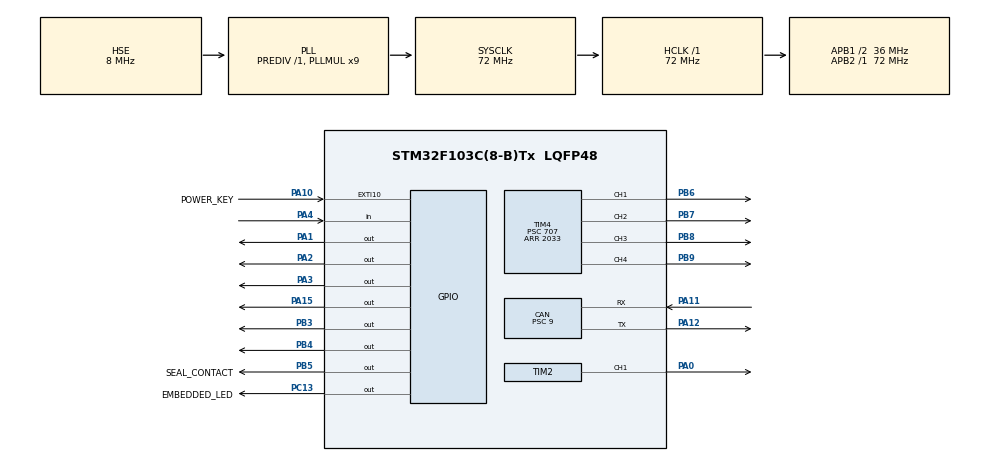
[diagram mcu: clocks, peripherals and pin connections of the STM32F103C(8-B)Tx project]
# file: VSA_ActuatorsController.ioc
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CAN.BS1=CAN_BS1_13TQ
CAN.BS2=CAN_BS2_2TQ
CAN.CalculateBaudRate=250000
CAN.CalculateTimeBit=4000
CAN.CalculateTimeQuantum=250.0
CAN.Prescaler=9
Mcu.Family=STM32F1
Mcu.Name=STM32F103C(8-B)Tx
Mcu.Package=LQFP48
NVIC.EXTI15_10_IRQn=true\:0\:0\:false\:false\:true\:true\:true\:true
NVIC.PriorityGroup=NVIC_PRIORITYGROUP_4
NVIC.USB_LP_CAN1_RX0_IRQn=true\:0\:0\:false\:false\:true\:true\:true\:true
PA0-WKUP.Signal=S_TIM2_CH1_ETR
PA1.Signal=GPIO_Output
PA10.GPIO_Label=POWER_KEY
PA10.GPIO_ModeDefaultEXTI=GPIO_MODE_IT_RISING_FALLING
PA10.GPIO_PuPd=GPIO_PULLUP
PA10.Signal=GPXTI10
PA11.Mode=CAN_Activate
PA11.Signal=CAN_RX
PA12.Mode=CAN_Activate
PA12.Signal=CAN_TX
PA14.Signal=SYS_JTCK-SWCLK
PA15.Signal=GPIO_Output
PA2.Signal=GPIO_Output
PA3.Signal=GPIO_Output
PA4.Signal=GPIO_Input
PB3.Signal=GPIO_Output
PB4.Signal=GPIO_Output
PB5.GPIO_Label=SEAL_CONTACT
PB5.Signal=GPIO_Output
PB6.Signal=S_TIM4_CH1
PB7.Signal=S_TIM4_CH2
PB8.Signal=S_TIM4_CH3
PB9.Signal=S_TIM4_CH4
PC13-TAMPER-RTC.GPIO_Label=EMBEDDED_LED
PC13-TAMPER-RTC.Signal=GPIO_Output
PD0-OSC_IN.Mode=HSE-External-Oscillator
PD0-OSC_IN.Signal=RCC_OSC_IN
PD1-OSC_OUT.Mode=HSE-External-Oscillator
PD1-OSC_OUT.Signal=RCC_OSC_OUT
ProjectManager.HeapSize=0x200
ProjectManager.StackSize=0x400
ProjectManager.TargetToolchain=STM32CubeIDE
RCC.AHBFreq_Value=72000000
RCC.APB1CLKDivider=RCC_HCLK_DIV2
RCC.APB1Freq_Value=36000000
RCC.APB1TimFreq_Value=72000000
RCC.APB2Freq_Value=72000000
RCC.APB2TimFreq_Value=72000000
RCC.HCLKFreq_Value=72000000
RCC.PLLMUL=RCC_PLL_MUL9
RCC.PLLSourceVirtual=RCC_PLLSOURCE_HSE
RCC.SYSCLKFreq_VALUE=72000000
RCC.SYSCLKSource=RCC_SYSCLKSOURCE_PLLCLK
RCC.USBFreq_Value=72000000
SH.S_TIM2_CH1_ETR.0=TIM2_CH1,PWM Generation1 CH1
SH.S_TIM4_CH1.0=TIM4_CH1,PWM Generation1 CH1
SH.S_TIM4_CH2.0=TIM4_CH2,PWM Generation2 CH2
SH.S_TIM4_CH3.0=TIM4_CH3,PWM Generation3 CH3
SH.S_TIM4_CH4.0=TIM4_CH4,PWM Generation4 CH4
TIM2.Channel-PWM\ Generation1\ CH1=TIM_CHANNEL_1
TIM2.Period=255
TIM2.Prescaler=250
TIM4.Channel-PWM\ Generation1\ CH1=TIM_CHANNEL_1
TIM4.Channel-PWM\ Generation2\ CH2=TIM_CHANNEL_2
TIM4.Channel-PWM\ Generation3\ CH3=TIM_CHANNEL_3
TIM4.Channel-PWM\ Generation4\ CH4=TIM_CHANNEL_4
TIM4.Period=2033
TIM4.Prescaler=707
VP_SYS_VS_ND.Mode=No_Debug
board=custom

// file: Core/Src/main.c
/* USER CODE BEGIN Header */
/**
  ******************************************************************************
  * @file           : main.c
  * @brief          : Main program body
  ******************************************************************************
  * @attention
  *
  * Copyright (c) 2026 STMicroelectronics.
  * All rights reserved.
  *
  * This software is licensed under terms that can be found in the LICENSE file
  * in the root directory of this software component.
  * If no LICENSE file comes with this software, it is provided AS-IS.
  *
  ******************************************************************************
  */
/* USER CODE END Header */
#include "main.h"
#include "vsa_actuators_controller.h"

void SystemClock_Config(void);

int main(void)
{
  HAL_Init();

  /* Configure the system clock */
  SystemClock_Config();

  /* Initialize all configured peripherals */
  MX_GPIO_Init();
  MX_CAN_Init();
  MX_TIM2_Init();
  MX_TIM4_Init();

  // Initialize Timers
  HAL_TIM_Base_Start(&htim2);
  HAL_TIM_Base_Start(&htim4);

  // Initialize PWM Pins
  HAL_TIM_PWM_Start(&htim2, TIM_CHANNEL_1); // Thruster Controller
  HAL_TIM_PWM_Start(&htim4, TIM_CHANNEL_1); // Servo 1
  HAL_TIM_PWM_Start(&htim4, TIM_CHANNEL_2); // Servo 2
  HAL_TIM_PWM_Start(&htim4, TIM_CHANNEL_3); // Servo 2
  HAL_TIM_PWM_Start(&htim4, TIM_CHANNEL_4); // Servo 3

  while (1)
  {
	  run();
  }
}

void SystemClock_Config(void)
{
  RCC_OscInitTypeDef RCC_OscInitStruct = {0};
  RCC_ClkInitTypeDef RCC_ClkInitStruct = {0};

  /** Initializes the RCC Oscillators according to the specified parameters
  * in the RCC_OscInitTypeDef structure.
  */
  RCC_OscInitStruct.OscillatorType = RCC_OSCILLATORTYPE_HSE;
  RCC_OscInitStruct.HSEState = RCC_HSE_ON;
  RCC_OscInitStruct.HSEPredivValue = RCC_HSE_PREDIV_DIV1;
  RCC_OscInitStruct.HSIState = RCC_HSI_ON;
  RCC_OscInitStruct.PLL.PLLState = RCC_PLL_ON;
  RCC_OscInitStruct.PLL.PLLSource = RCC_PLLSOURCE_HSE;
  RCC_OscInitStruct.PLL.PLLMUL = RCC_PLL_MUL9;
  if (HAL_RCC_OscConfig(&RCC_OscInitStruct) != HAL_OK)
  {
    Error_Handler();
  }

  /** Initializes the CPU, AHB and APB buses clocks
  */
  RCC_ClkInitStruct.ClockType = RCC_CLOCKTYPE_HCLK|RCC_CLOCKTYPE_SYSCLK
                              |RCC_CLOCKTYPE_PCLK1|RCC_CLOCKTYPE_PCLK2;
  RCC_ClkInitStruct.SYSCLKSource = RCC_SYSCLKSOURCE_PLLCLK;
  RCC_ClkInitStruct.AHBCLKDivider = RCC_SYSCLK_DIV1;
  RCC_ClkInitStruct.APB1CLKDivider = RCC_HCLK_DIV2;
  RCC_ClkInitStruct.APB2CLKDivider = RCC_HCLK_DIV1;

  if (HAL_RCC_ClockConfig(&RCC_ClkInitStruct, FLASH_LATENCY_2) != HAL_OK)
  {
    Error_Handler();
  }
}

/* USER CODE BEGIN 4 */
void HAL_CAN_RxFifo0MsgPendingCallback(CAN_HandleTypeDef *hcan)
{
	can_rx_interrupt_callback(hcan);
}

/* USER CODE END 4 */

void Error_Handler(void)
{
  __disable_irq();
  while (1)
  {
  }
}
